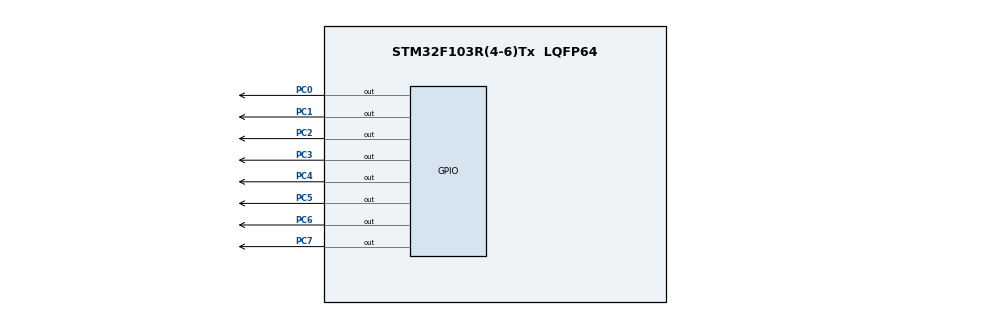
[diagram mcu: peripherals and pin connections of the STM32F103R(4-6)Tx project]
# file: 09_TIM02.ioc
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Mcu.Family=STM32F1
Mcu.Name=STM32F103R(4-6)Tx
Mcu.Package=LQFP64
NVIC.PriorityGroup=NVIC_PRIORITYGROUP_4
NVIC.TIM3_IRQn=true\:0\:0\:false\:false\:true\:true\:true\:true
PC0.Signal=GPIO_Output
PC1.Signal=GPIO_Output
PC2.Signal=GPIO_Output
PC3.Signal=GPIO_Output
PC4.Signal=GPIO_Output
PC5.Signal=GPIO_Output
PC6.Signal=GPIO_Output
PC7.Signal=GPIO_Output
ProjectManager.HeapSize=0x200
ProjectManager.StackSize=0x400
ProjectManager.TargetToolchain=MDK-ARM V5.32
RCC.APB1Freq_Value=8000000
RCC.APB2Freq_Value=8000000
TIM3.Period=999
TIM3.Prescaler=3999
VP_SYS_VS_ND.Mode=No_Debug
VP_TIM3_VS_ClockSourceINT.Mode=Internal
board=custom

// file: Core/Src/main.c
/* USER CODE BEGIN Header */
/**
  ******************************************************************************
  * @file           : main.c
  * @brief          : Main program body
  ******************************************************************************
  * @attention
  *
  * Copyright (c) 2022 STMicroelectronics.
  * All rights reserved.
  *
  * This software is licensed under terms that can be found in the LICENSE file
  * in the root directory of this software component.
  * If no LICENSE file comes with this software, it is provided AS-IS.
  *
  ******************************************************************************
  */
/* USER CODE END Header */
#include "main.h"
#include "tim.h"
#include "gpio.h"

void SystemClock_Config(void);

int main(void)
{

  /* MCU Configuration--------------------------------------------------------*/

  /* Reset of all peripherals, Initializes the Flash interface and the Systick. */
  HAL_Init();

  /* Configure the system clock */
  SystemClock_Config();

  /* Initialize all configured peripherals */
  MX_GPIO_Init();
  MX_TIM3_Init();
  /* USER CODE BEGIN 2 */
	LL_GPIO_WriteOutputPort(GPIOC, 0xfe);
	HAL_TIM_Base_Start_IT(&htim3);  //初始化定时器
  /* USER CODE END 2 */

  /* Infinite loop */
  while (1)
  {

  }
}

void SystemClock_Config(void)
{
  RCC_OscInitTypeDef RCC_OscInitStruct = {0};
  RCC_ClkInitTypeDef RCC_ClkInitStruct = {0};

  /** Initializes the RCC Oscillators according to the specified parameters
  * in the RCC_OscInitTypeDef structure.
  */
  RCC_OscInitStruct.OscillatorType = RCC_OSCILLATORTYPE_HSI;
  RCC_OscInitStruct.HSIState = RCC_HSI_ON;
  RCC_OscInitStruct.HSICalibrationValue = RCC_HSICALIBRATION_DEFAULT;
  RCC_OscInitStruct.PLL.PLLState = RCC_PLL_NONE;
  if (HAL_RCC_OscConfig(&RCC_OscInitStruct) != HAL_OK)
  {
    Error_Handler();
  }

  /** Initializes the CPU, AHB and APB buses clocks
  */
  RCC_ClkInitStruct.ClockType = RCC_CLOCKTYPE_HCLK|RCC_CLOCKTYPE_SYSCLK
                              |RCC_CLOCKTYPE_PCLK1|RCC_CLOCKTYPE_PCLK2;
  RCC_ClkInitStruct.SYSCLKSource = RCC_SYSCLKSOURCE_HSI;
  RCC_ClkInitStruct.AHBCLKDivider = RCC_SYSCLK_DIV1;
  RCC_ClkInitStruct.APB1CLKDivider = RCC_HCLK_DIV1;
  RCC_ClkInitStruct.APB2CLKDivider = RCC_HCLK_DIV1;

  if (HAL_RCC_ClockConfig(&RCC_ClkInitStruct, FLASH_LATENCY_0) != HAL_OK)
  {
    Error_Handler();
  }
}

/* USER CODE BEGIN 4 */
void HAL_TIM_PeriodElapsedCallback(TIM_HandleTypeDef *htim)
{
	static uint8_t counter = 0;
	if(htim == &htim3)  //定时器3中断
	{
		counter++;
		if(counter>=8) counter=0;
		LL_GPIO_WriteOutputPort(GPIOC, (0xfe<<counter)|(0xfe>>(8-counter)));  //流水灯状态改变一次
	}
}
/* USER CODE END 4 */

void Error_Handler(void)
{
  __disable_irq();
  while (1)
  {
  }
}
